# A31G11x_series register map
Vendor: ABOV Semiconductor Co., Ltd.; Series: A31G11x_series; File version: 1.0
CPU: CM0PLUS r0p1, little endian, no MPU, no FPU, VTOR, 2 interrupt priority bits
Registers are 32-bit, read-write, reset 0x0 unless marked. A register's access mark holds for its fields unless they carry their own. Offsets are from the block's base; [hi:lo] are bit positions; {n}, {i} and the like mark numbered series; 'fields as' and 'values as' point back to an identical list.

## CRC — CYCLIC REDUNDANCY CHECK AND CHECKSUM
Base 0x30001000
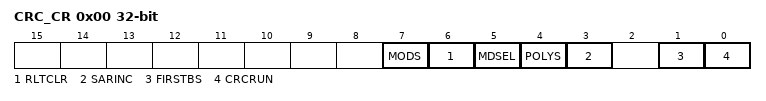
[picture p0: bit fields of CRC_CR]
0x00 CRC_CR — CRC/Checksum Control Register. Notes: 1. The CRCRLT register and the CRC/Checksum block should be initialized by writing "1b" to the RLTCLR bit before a new CRC/Checksum calculation. 2. The CRCRUN bit should be set to "1b" last time after setting appropriate values to the registers. 3. On the user mode, it will be calculated every writing data to the CRCIN register during CRCRUN==1. 4. On the user mode with SARINC==0, the block is finished by writing "0b" to the CRCRUN bit. 4. It is prohibited writing any data to the CRCIN register during CRCRUN==0. 5. The checksum is calculated by byte unit. Ex) On 0x34A7E991, CRCRLT = 0x34 + 0xA7 + 0xE9 + 0x91.
  [7] MODS — User/Auto Mode Selection bit
  [6] RLTCLR — CRC/Checksum Result Data Register (CRCRLT) Initialization bit
  [5] MDSEL — CRC/Checksum Selection bit
  [4] POLYS — Polynomial Selection bit (CRC only)
  [3] SARINC — CRC/Checksum Start Address Auto Increment Control bit (User mode only)
  [1] FIRSTBS — First Shifted-in Selection bit (CRC only)
  [0] CRCRUN — CRC/Checksum Start Control and Busy bit
0x04 CRC_IN — CRC/Checksum Input Data Register
0x08 CRC_RLT ro reset 0xFFFF (reset mask 0xFFFF) — CRC/Checksum Result Data Register
0x0C CRC_INIT (reset mask 0xFFFF) — CRC/Checksum Initial Data Register
0x10 CRC_SADR reset 0x10000000 (reset mask 0xFFFFFFFC) — CRC/Checksum Start Address Register. Note: The LSB-7bits of the start address should be "0x00" on the "Auto mode".
0x14 CRC_EADR reset 0x10007FFC (reset mask 0xFFFFFFFC) — CRC/Checksum End Address Register. Note: The LSB-7bits of the end address should be "0x7c" on the "Auto mode".

## INT — Interrupt
Base 0x40001000
0x04 INTC_PBTRIG (reset mask 0xFF) — Port B Interrupt Trigger Selection Register
  [n] ITRIG{n} (n=2..7) — Pin {n} Interrupt Trigger Selection bit
  [?] ITRIG1 — Pin 1 Interrupt Trigger Selection bit
  [0] ITRIG0 — Pin 0 Interrupt Trigger Selection bit
0x08 INTC_PCTRIG (reset mask 0xF) — Port C Interrupt Trigger Selection Register
  fields as INTC_PBTRIG
0x10 INTC_PETRIG (reset mask 0xF) — Port E Interrupt Trigger Selection Register
  fields as INTC_PBTRIG
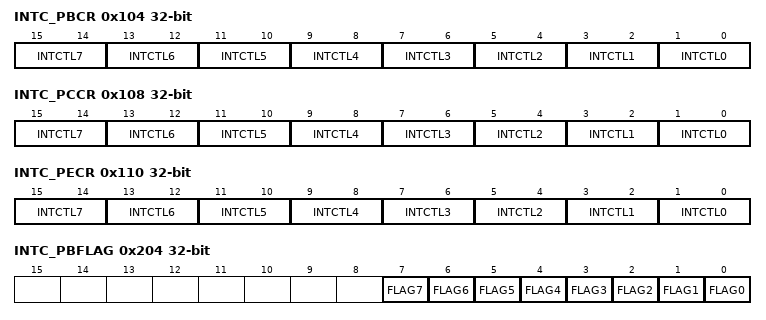
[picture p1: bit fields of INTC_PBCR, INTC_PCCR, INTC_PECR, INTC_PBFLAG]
0x104 INTC_PBCR — Port B Interrupt Control Register
  [2n+1:2n] INTCTL{n} (n=0..7) — Pin {n} Interrupt Control bits
0x108 INTC_PCCR (reset mask 0xFF) — Port C Interrupt Control Register
  [2n+1:2n] INTCTL{n} (n=0..7) — Pin {n} Interrupt Control bits
0x110 INTC_PECR (reset mask 0xFF) — Port E Interrupt Control Register
  [2n+1:2n] INTCTL{n} (n=0..7) — Pin {n} Interrupt Control bits
0x204 INTC_PBFLAG — Port B Interrupt Flag Register
  [n] FLAG{n} (n=0..7) — Pin {n} Interrupt Flag bit
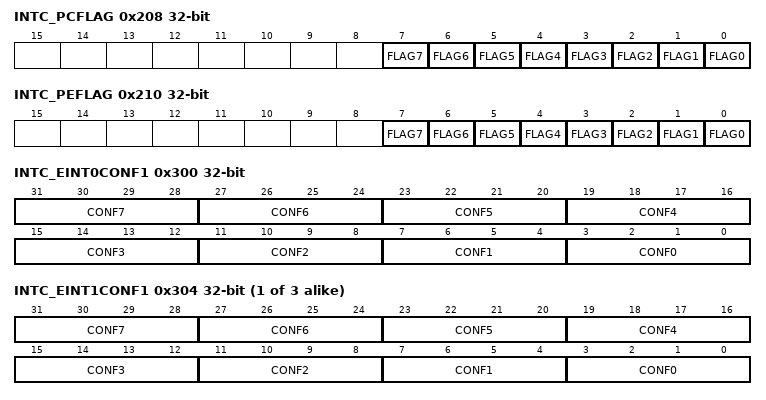
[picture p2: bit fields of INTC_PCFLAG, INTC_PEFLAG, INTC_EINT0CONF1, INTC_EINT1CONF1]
0x208 INTC_PCFLAG (reset mask 0xF) — Port C Interrupt Flag Register
  [n] FLAG{n} (n=0..7) — Pin {n} Interrupt Flag bit
0x210 INTC_PEFLAG (reset mask 0xF) — Port E Interrupt Flag Register
  [n] FLAG{n} (n=0..7) — Pin {n} Interrupt Flag bit
0x300 INTC_EINT0CONF1 — External Interrupt 0 Configuration Register 1
  [4n+3:4n] CONF{n} (n=0..7) — Pin {n} Configuration bits for External Interrupt Group
{0x300+4i} INTC_EINT{i}CONF1 (i=1..3) — External Interrupt Configuration Register 1
  fields as INTC_EINT0CONF1
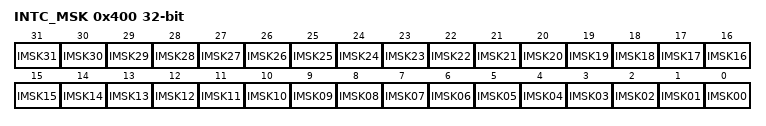
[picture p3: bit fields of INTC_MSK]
0x400 INTC_MSK — Interrupt Source Mask Register
  [31] IMSK31 — INT 31 Wake-up Source Mask bit from "Sleep"/"Deep Sleep" mode
    0=MASK; 1=UNMASK
  [n] IMSK{n} (n=19..30) — INT {n} Wake-up Source Mask bit from "Sleep"/"Deep Sleep" mode
  [n] IMSK{n:02} (n=0..18) — INT {n} Interrupt Source Mask bit from "Sleep"/"Deep Sleep" mode

## WDT — WATCH-DOG TIMER
Base 0x40001A00
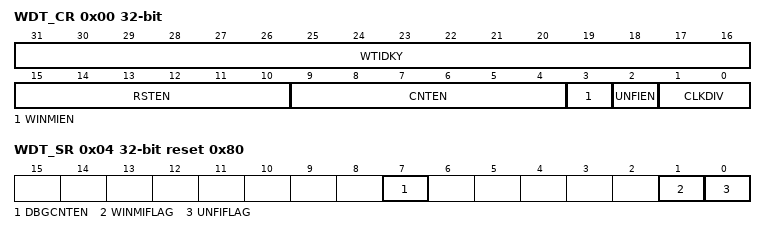
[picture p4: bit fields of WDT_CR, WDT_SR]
0x00 WDT_CR — Watch-dog Timer Control Register
  [31:16] WTIDKY wo — Write Identification Key. On writes, write 0x5A69 to these bits, otherwise the write is ignored.
  [15:10] RSTEN — Watch-dog Timer Reset Enable bits
    37=DISABLE_WDT_RST (Disable watch-dog timer reset); 0=ENABLE_WDT_RST (Enable watch-dog timer reset)
  [9:4] CNTEN — Watch-dog Timer Counter Enable bits
    26=DISABLE_WDT_CNT (Disable watch-dog timer counter); 0=ENABLE_WDT_CNT (Enable watch-dog timer counter)
  [3] WINMIEN — Watch-dog Timer Window Match Interrupt Enable bit
    0=DISABLE_WDT_WDM_INT (Disable window data match interrupt); 1=ENABLE_WDT_WDM_INT (Enable window data match interrupt)
  [2] UNFIEN — Watch-dog Timer Underflow Interrupt Enable bit
    0=DISABLE_WDT_UDF_INT (Disable watch-dog timer underflow interrupt); 1=ENABLE_WDT_UDF_INT (Enable watch-dog timer underflow interrupt)
  [1:0] CLKDIV — Watch-dog Timer Clock Divider bits, The clock which is selected by PPCLKSR[0]
    0=WDT_CLK_DIVIDER_4 (fWDT/4); 1=WDT_CLK_DIVIDER_16 (fWDT/16); 2=WDT_CLK_DIVIDER_64 (fWDT/64); 3=WDT_CLK_DIVIDER_256 (fWDT/256)
0x04 WDT_SR reset 0x80 — Watch-dog Timer Status Register
  [7] DBGCNTEN — Watch-dog Timer Counter Enable bit. When the core is halted in the debug mode. Note: This bit is cleared to "0b" only by POR reset.
    0=RUN_CORE_HALTED (The watch-dog timer counter continues even if the core is halted.); 1=STOP_CORE_HALTED (The watch-dog timer counter is stopped when the core is halted.)
  [1] WINMIFLAG — Watch-dog Timer Window Match Interrupt Flag bit
    0=WDT_WDM_IF_CLR (No request occurred); 1=WDT_WDM_IF_SET (Request occurred, This bit is cleared to '0' when write '1'.)
  [0] UNFIFLAG — Watch-dog Timer Underflow Interrupt Flag bit
    0=WDT_UDF_IF_CLR (No request occurred); 1=WDT_UDF_IF_SET (Request occurred, This bit is cleared to '0' when write '1'.)
0x08 WDT_DR reset 0xFFF — Watch-dog Timer Data Register
  [23:0] DATA — Watch-dog Timer Data bits. The range is 0x000000 to 0xFFFFFF.
0x0C WDT_CNT ro reset 0xFFF — Watch-dog Timer Counter Register
  [23:0] CNT — Watch-dog Timer Counter bits.
0x10 WDT_WINDR reset 0x1FFF — Watch-dog Timer Window Data Register (Note: Once any value is written to this window data register, the register can't be changed until a system reset.)
  [23:0] WDATA — Watch-dog Timer Window Data bits. The range is 0x000000 to 0xFFFFFF.
0x14 WDT_CNTR wo — Watch-dog Timer Counter Reload Register
  [7:0] CNTR — Watch-dog Timer Counter Reload bits.
    106=RELOAD_WDTDR (Reload the WDTDR value to watch-dog timer counter and re-start. (Automatically cleared to "0x00" after operation)); 0=UNLOAD_WDTDR (No effect)

## Notices in the file
Copyright (C) 2012-2014 ARM Limited. All rights reserved.
Purpose: System Viewer Description (SVD) Example (Schema Version 1.1)
This is a description of a none-existent and incomplete device
for demonstration purposes only.
Redistribution and use in source and binary forms, with or without
modification, are permitted provided that the following conditions are met:
- Redistributions of source code must retain the above copyright
notice, this list of conditions and the following disclaimer.
- Redistributions in binary form must reproduce the above copyright
notice, this list of conditions and the following disclaimer in the
documentation and/or other materials provided with the distribution.
- Neither the name of ARM nor the names of its contributors may be used
to endorse or promote products derived from this software without
specific prior written permission.
THIS SOFTWARE IS PROVIDED BY THE COPYRIGHT HOLDERS AND CONTRIBUTORS "AS IS"
AND ANY EXPRESS OR IMPLIED WARRANTIES, INCLUDING, BUT NOT LIMITED TO, THE
IMPLIED WARRANTIES OF MERCHANTABILITY AND FITNESS FOR A PARTICULAR PURPOSE
ARE DISCLAIMED. IN NO EVENT SHALL COPYRIGHT HOLDERS AND CONTRIBUTORS BE
LIABLE FOR ANY DIRECT, INDIRECT, INCIDENTAL, SPECIAL, EXEMPLARY, OR
CONSEQUENTIAL DAMAGES (INCLUDING, BUT NOT LIMITED TO, PROCUREMENT OF
SUBSTITUTE GOODS OR SERVICES; LOSS OF USE, DATA, OR PROFITS; OR BUSINESS
INTERRUPTION) HOWEVER CAUSED AND ON ANY THEORY OF LIABILITY, WHETHER IN
CONTRACT, STRICT LIABILITY, OR TORT (INCLUDING NEGLIGENCE OR OTHERWISE)
ARISING IN ANY WAY OUT OF THE USE OF THIS SOFTWARE, EVEN IF ADVISED OF THE
POSSIBILITY OF SUCH DAMAGE.
